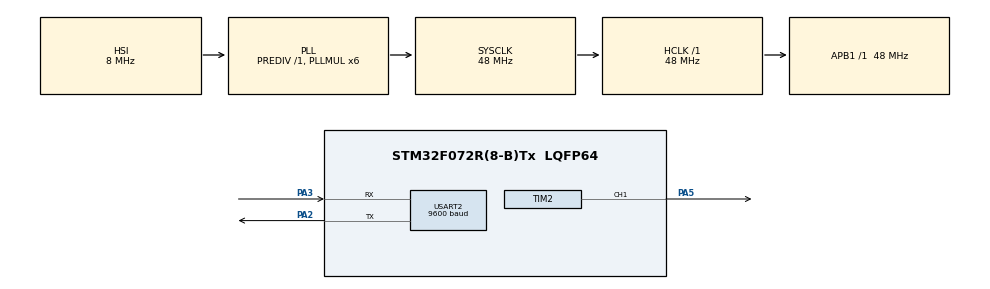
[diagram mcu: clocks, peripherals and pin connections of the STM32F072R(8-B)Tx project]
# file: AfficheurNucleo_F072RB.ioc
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Mcu.Family=STM32F0
Mcu.Name=STM32F072R(8-B)Tx
Mcu.Package=LQFP64
NVIC.TIM6_DAC_IRQn=true\:0\:0\:false\:false\:true\:true
PA2.Mode=Asynchronous
PA2.Signal=USART2_TX
PA3.Mode=Asynchronous
PA3.Signal=USART2_RX
PA5.Signal=S_TIM2_CH1_ETR
ProjectManager.HeapSize=0x200
ProjectManager.StackSize=0x400
ProjectManager.TargetToolchain=TrueSTUDIO
RCC.AHBFreq_Value=48000000
RCC.APB1Freq_Value=48000000
RCC.APB1TimFreq_Value=48000000
RCC.HCLKFreq_Value=48000000
RCC.PLLMUL=RCC_PLL_MUL6
RCC.SYSCLKFreq_VALUE=48000000
RCC.SYSCLKSource=RCC_SYSCLKSOURCE_PLLCLK
SH.S_TIM2_CH1_ETR.0=TIM2_CH1,PWM Generation1 CH1
TIM2.Channel-PWM\ Generation1\ CH1=TIM_CHANNEL_1
TIM2.Period=200000-1
TIM2.Prescaler=48-1
TIM2.Pulse-PWM\ Generation1\ CH1=100000-1
TIM6.Period=100-1
TIM6.Prescaler=48000
USART2.BaudRate=9600
USART2.VirtualMode-Asynchronous=VM_ASYNC
USART2.WordLength=WORDLENGTH_8B
VP_TIM2_VS_ClockSourceINT.Mode=Internal
VP_TIM6_VS_ClockSourceINT.Mode=Enable_Timer
board=AfficheurNucleo_F072RB

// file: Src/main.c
/**
  ******************************************************************************
  * @file           : main.c
  * @brief          : Main program body
  ******************************************************************************
  ** This notice applies to any and all portions of this file
  * that are not between comment pairs USER CODE BEGIN and
  * USER CODE END. Other portions of this file, whether
  * inserted by the user or by software development tools
  * are owned by their respective copyright owners.
  *
  * COPYRIGHT(c) 2020 STMicroelectronics
  *
  * Redistribution and use in source and binary forms, with or without modification,
  * are permitted provided that the following conditions are met:
  *   1. Redistributions of source code must retain the above copyright notice,
  *      this list of conditions and the following disclaimer.
  *   2. Redistributions in binary form must reproduce the above copyright notice,
  *      this list of conditions and the following disclaimer in the documentation
  *      and/or other materials provided with the distribution.
  *   3. Neither the name of STMicroelectronics nor the names of its contributors
  *      may be used to endorse or promote products derived from this software
  *      without specific prior written permission.
  *
  * THIS SOFTWARE IS PROVIDED BY THE COPYRIGHT HOLDERS AND CONTRIBUTORS "AS IS"
  * AND ANY EXPRESS OR IMPLIED WARRANTIES, INCLUDING, BUT NOT LIMITED TO, THE
  * IMPLIED WARRANTIES OF MERCHANTABILITY AND FITNESS FOR A PARTICULAR PURPOSE ARE
  * DISCLAIMED. IN NO EVENT SHALL THE COPYRIGHT HOLDER OR CONTRIBUTORS BE LIABLE
  * FOR ANY DIRECT, INDIRECT, INCIDENTAL, SPECIAL, EXEMPLARY, OR CONSEQUENTIAL
  * DAMAGES (INCLUDING, BUT NOT LIMITED TO, PROCUREMENT OF SUBSTITUTE GOODS OR
  * SERVICES; LOSS OF USE, DATA, OR PROFITS; OR BUSINESS INTERRUPTION) HOWEVER
  * CAUSED AND ON ANY THEORY OF LIABILITY, WHETHER IN CONTRACT, STRICT LIABILITY,
  * OR TORT (INCLUDING NEGLIGENCE OR OTHERWISE) ARISING IN ANY WAY OUT OF THE USE
  * OF THIS SOFTWARE, EVEN IF ADVISED OF THE POSSIBILITY OF SUCH DAMAGE.
  *
  ******************************************************************************
  */
#include "main.h"
#include "stm32f0xx_hal.h"

/* USER CODE BEGIN Includes */
#include "Amadou_Charles_Functions.h"
/* USER CODE END Includes */

TIM_HandleTypeDef htim2;
TIM_HandleTypeDef htim6;

UART_HandleTypeDef huart2;

/* USER CODE BEGIN PV */
/* Private variables ---------------------------------------------------------*/
char CaractereRecu;
/* USER CODE END PV */

void SystemClock_Config(void);
static void MX_GPIO_Init(void);
static void MX_TIM2_Init(void);
static void MX_TIM6_Init(void);
static void MX_USART2_UART_Init(void);
void HAL_TIM_MspPostInit(TIM_HandleTypeDef *htim);

/* USER CODE BEGIN PFP */
/* Private function prototypes -----------------------------------------------*/

/* USER CODE END PFP */

int main(void)
{

  /* MCU Configuration----------------------------------------------------------*/

  /* Reset of all peripherals, Initializes the Flash interface and the Systick. */
  HAL_Init();

  /* USER CODE BEGIN Init */
  HAL_TIM_PWM_Start(&htim2, TIM_CHANNEL_1);
  /* USER CODE END Init */

  /* Configure the system clock */
  SystemClock_Config();

  /* Initialize all configured peripherals */
  MX_GPIO_Init();
  MX_TIM2_Init();
  MX_TIM6_Init();
  MX_USART2_UART_Init();
  /* USER CODE BEGIN 2 */

  // Changement du rapport cyclique
  TIM2->CCR1 = 50;  //25% = 50/200
  /* USER CODE END 2 */

  /* Infinite loop */
  /* USER CODE BEGIN WHILE */
  while (1)
  {
	  /*RESET_PATTE(GPIOA, 5);
	  Attente(1106);
	  SET_PATTE(GPIOA, 5);
	  Attente(1106);*/

  /* USER CODE END WHILE */

  /* USER CODE BEGIN 3 */

	  while (!(USART2->ISR & (1<<5))){
		  // Tant que le caractère n'est pas reçu on attend ici
	  }
	  // arriver ici : caractère reçu
	  // lecture du caractère

	  CaractereRecu = USART2->RDR;

	  // traitement du caractère
	  CaractereRecu = CaractereRecu + 1;

	  // on attend que le buffer de transmission soit libre
	  while (!(USART2->ISR & (1<<5))){
		  // Tant que le caractère n'est pas reçu on attend ici
	  }

	  // Transmission
	  USART2->TDR = CaractereRecu;

  }
  /* USER CODE END 3 */

}

void SystemClock_Config(void)
{

  RCC_OscInitTypeDef RCC_OscInitStruct;
  RCC_ClkInitTypeDef RCC_ClkInitStruct;
  RCC_PeriphCLKInitTypeDef PeriphClkInit;

    /**Initializes the CPU, AHB and APB busses clocks
    */
  RCC_OscInitStruct.OscillatorType = RCC_OSCILLATORTYPE_HSI;
  RCC_OscInitStruct.HSIState = RCC_HSI_ON;
  RCC_OscInitStruct.HSICalibrationValue = 16;
  RCC_OscInitStruct.PLL.PLLState = RCC_PLL_ON;
  RCC_OscInitStruct.PLL.PLLSource = RCC_PLLSOURCE_HSI;
  RCC_OscInitStruct.PLL.PLLMUL = RCC_PLL_MUL6;
  RCC_OscInitStruct.PLL.PREDIV = RCC_PREDIV_DIV1;
  if (HAL_RCC_OscConfig(&RCC_OscInitStruct) != HAL_OK)
  {
    _Error_Handler(__FILE__, __LINE__);
  }

    /**Initializes the CPU, AHB and APB busses clocks
    */
  RCC_ClkInitStruct.ClockType = RCC_CLOCKTYPE_HCLK|RCC_CLOCKTYPE_SYSCLK
                              |RCC_CLOCKTYPE_PCLK1;
  RCC_ClkInitStruct.SYSCLKSource = RCC_SYSCLKSOURCE_PLLCLK;
  RCC_ClkInitStruct.AHBCLKDivider = RCC_SYSCLK_DIV1;
  RCC_ClkInitStruct.APB1CLKDivider = RCC_HCLK_DIV1;

  if (HAL_RCC_ClockConfig(&RCC_ClkInitStruct, FLASH_LATENCY_1) != HAL_OK)
  {
    _Error_Handler(__FILE__, __LINE__);
  }

  PeriphClkInit.PeriphClockSelection = RCC_PERIPHCLK_USART2;
  PeriphClkInit.Usart2ClockSelection = RCC_USART2CLKSOURCE_PCLK1;
  if (HAL_RCCEx_PeriphCLKConfig(&PeriphClkInit) != HAL_OK)
  {
    _Error_Handler(__FILE__, __LINE__);
  }

    /**Configure the Systick interrupt time
    */
  HAL_SYSTICK_Config(HAL_RCC_GetHCLKFreq()/1000);

    /**Configure the Systick
    */
  HAL_SYSTICK_CLKSourceConfig(SYSTICK_CLKSOURCE_HCLK);

  /* SysTick_IRQn interrupt configuration */
  HAL_NVIC_SetPriority(SysTick_IRQn, 0, 0);
}

/* TIM2 init function */
static void MX_TIM2_Init(void)
{

  TIM_ClockConfigTypeDef sClockSourceConfig;
  TIM_MasterConfigTypeDef sMasterConfig;
  TIM_OC_InitTypeDef sConfigOC;

  htim2.Instance = TIM2;
  htim2.Init.Prescaler = 48-1;
  htim2.Init.CounterMode = TIM_COUNTERMODE_UP;
  htim2.Init.Period = 200000-1;
  htim2.Init.ClockDivision = TIM_CLOCKDIVISION_DIV1;
  htim2.Init.AutoReloadPreload = TIM_AUTORELOAD_PRELOAD_DISABLE;
  if (HAL_TIM_Base_Init(&htim2) != HAL_OK)
  {
    _Error_Handler(__FILE__, __LINE__);
  }

  sClockSourceConfig.ClockSource = TIM_CLOCKSOURCE_INTERNAL;
  if (HAL_TIM_ConfigClockSource(&htim2, &sClockSourceConfig) != HAL_OK)
  {
    _Error_Handler(__FILE__, __LINE__);
  }

  if (HAL_TIM_PWM_Init(&htim2) != HAL_OK)
  {
    _Error_Handler(__FILE__, __LINE__);
  }

  sMasterConfig.MasterOutputTrigger = TIM_TRGO_RESET;
  sMasterConfig.MasterSlaveMode = TIM_MASTERSLAVEMODE_DISABLE;
  if (HAL_TIMEx_MasterConfigSynchronization(&htim2, &sMasterConfig) != HAL_OK)
  {
    _Error_Handler(__FILE__, __LINE__);
  }

  sConfigOC.OCMode = TIM_OCMODE_PWM1;
  sConfigOC.Pulse = 100000-1;
  sConfigOC.OCPolarity = TIM_OCPOLARITY_HIGH;
  sConfigOC.OCFastMode = TIM_OCFAST_DISABLE;
  if (HAL_TIM_PWM_ConfigChannel(&htim2, &sConfigOC, TIM_CHANNEL_1) != HAL_OK)
  {
    _Error_Handler(__FILE__, __LINE__);
  }

  HAL_TIM_MspPostInit(&htim2);

}

/* TIM6 init function */
static void MX_TIM6_Init(void)
{

  TIM_MasterConfigTypeDef sMasterConfig;

  htim6.Instance = TIM6;
  htim6.Init.Prescaler = 48000;
  htim6.Init.CounterMode = TIM_COUNTERMODE_UP;
  htim6.Init.Period = 100-1;
  htim6.Init.AutoReloadPreload = TIM_AUTORELOAD_PRELOAD_DISABLE;
  if (HAL_TIM_Base_Init(&htim6) != HAL_OK)
  {
    _Error_Handler(__FILE__, __LINE__);
  }

  sMasterConfig.MasterOutputTrigger = TIM_TRGO_RESET;
  sMasterConfig.MasterSlaveMode = TIM_MASTERSLAVEMODE_DISABLE;
  if (HAL_TIMEx_MasterConfigSynchronization(&htim6, &sMasterConfig) != HAL_OK)
  {
    _Error_Handler(__FILE__, __LINE__);
  }

}

/* USART2 init function */
static void MX_USART2_UART_Init(void)
{

  huart2.Instance = USART2;
  huart2.Init.BaudRate = 9600;
  huart2.Init.WordLength = UART_WORDLENGTH_8B;
  huart2.Init.StopBits = UART_STOPBITS_1;
  huart2.Init.Parity = UART_PARITY_NONE;
  huart2.Init.Mode = UART_MODE_TX_RX;
  huart2.Init.HwFlowCtl = UART_HWCONTROL_NONE;
  huart2.Init.OverSampling = UART_OVERSAMPLING_16;
  huart2.Init.OneBitSampling = UART_ONE_BIT_SAMPLE_DISABLE;
  huart2.AdvancedInit.AdvFeatureInit = UART_ADVFEATURE_NO_INIT;
  if (HAL_UART_Init(&huart2) != HAL_OK)
  {
    _Error_Handler(__FILE__, __LINE__);
  }

}

/** Pinout Configuration
*/
static void MX_GPIO_Init(void)
{

  /* GPIO Ports Clock Enable */
  __HAL_RCC_GPIOA_CLK_ENABLE();

}

void _Error_Handler(char *file, int line)
{
  while(1)
  {
  }
}

/************************ (C) COPYRIGHT STMicroelectronics *****END OF FILE****/
